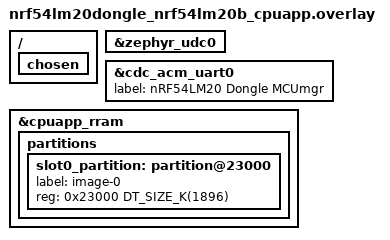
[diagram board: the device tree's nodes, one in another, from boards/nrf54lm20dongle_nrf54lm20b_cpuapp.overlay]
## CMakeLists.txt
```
#
# Copyright (c) 2026 Nordic Semiconductor ASA
#
# SPDX-License-Identifier: LicenseRef-Nordic-5-Clause
#

cmake_minimum_required(VERSION 3.20.0)
find_package(Zephyr REQUIRED HINTS $ENV{ZEPHYR_BASE})
project(usb_mcumgr)

target_sources(app PRIVATE ${ZEPHYR_BASE}/samples/subsys/mgmt/mcumgr/smp_svr/src/main.c)
target_sources_ifdef(CONFIG_SAMPLE_USB_MCUMGR_LED_THREAD app PRIVATE src/led_thread.c)
```

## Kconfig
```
#
# Copyright (c) 2026 Nordic Semiconductor ASA
#
# SPDX-License-Identifier: LicenseRef-Nordic-5-Clause
#

menu "USB MCUmgr firmware loader sample"

config SAMPLE_USB_MCUMGR_LED_THREAD
	bool "LED thread"
	default y if BOARD_NRF54LM20DONGLE
	depends on $(dt_alias_enabled,led0)
	select GPIO
	help
	  Start a low-priority thread that blinks the LED selected with the
	  devicetree alias "led0".

endmenu

source "Kconfig.zephyr"
```

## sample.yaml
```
sample:
  name: Minimal USB CDC-ACM SMP firmware loader sample
common:
  sysbuild: true
  build_only: true
tests:
  sample.fw_loader_usb_mcumgr:
    tags:
      - ci_samples_dfu
    platform_allow:
      - nrf54lm20dk/nrf54lm20a/cpuapp
      - nrf54lm20dongle/nrf54lm20b/cpuapp
    integration_platforms:
      - nrf54lm20dk/nrf54lm20a/cpuapp
      - nrf54lm20dongle/nrf54lm20b/cpuapp
```

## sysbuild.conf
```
# Enable MCUboot bootloader support
SB_CONFIG_BOOTLOADER_MCUBOOT=y
SB_CONFIG_PARTITION_MANAGER=n
SB_CONFIG_MCUBOOT_SYSBUILD_SIGN=n
```

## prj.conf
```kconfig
# Enable MCUmgr and dependencies.
CONFIG_NET_BUF=y
CONFIG_ZCBOR=y
CONFIG_CRC=y
CONFIG_MCUMGR=y
CONFIG_STREAM_FLASH=y
CONFIG_FLASH_MAP=y

# Some command handlers require a large stack.
CONFIG_SYSTEM_WORKQUEUE_STACK_SIZE=2304
CONFIG_MAIN_STACK_SIZE=2176

# Ensure an MCUboot-compatible binary is generated.
CONFIG_BOOTLOADER_MCUBOOT=y

# Enable flash operations.
CONFIG_FLASH=y

# Enable most core commands.
CONFIG_IMG_MANAGER=y
CONFIG_MCUMGR_GRP_IMG=y
CONFIG_MCUMGR_GRP_OS=y
CONFIG_MCUMGR_GRP_OS_BOOTLOADER_INFO=y
CONFIG_MCUMGR_GRP_OS_ECHO=n
CONFIG_MCUMGR_GRP_OS_INFO=n

# Enable the Shell mcumgr transport.
CONFIG_BASE64=y
CONFIG_CRC=y

CONFIG_MCUMGR_TRANSPORT_NETBUF_SIZE=1220
CONFIG_MCUMGR_GRP_OS_MCUMGR_PARAMS=y
CONFIG_MCUMGR_TRANSPORT_WORKQUEUE_STACK_SIZE=4608

# Enable the storage erase command.
CONFIG_MCUMGR_GRP_ZBASIC=y
CONFIG_MCUMGR_GRP_ZBASIC_STORAGE_ERASE=y

# Disable shell commands that are not needed
CONFIG_CLOCK_CONTROL_NRF_SHELL=n
CONFIG_DEVICE_SHELL=n
CONFIG_DEVMEM_SHELL=n
CONFIG_FLASH_SHELL=n

# Disable unneeded drivers, peripherals and features to optimize for size
CONFIG_SIZE_OPTIMIZATIONS=y

# Enable LTO
CONFIG_LTO=y
CONFIG_ISR_TABLES_LOCAL_DECLARATION=y

CONFIG_I2C=n
CONFIG_WATCHDOG=n
CONFIG_SPI_NOR=n
CONFIG_GPIO=n

CONFIG_FPU=n

CONFIG_BOOT_BANNER=n
CONFIG_NCS_BOOT_BANNER=n
CONFIG_BOOT_DELAY=0
CONFIG_PRINTK=n

CONFIG_ARM_MPU=n

CONFIG_TIMESLICING=n
CONFIG_COMMON_LIBC_MALLOC=y
CONFIG_LOG=n

CONFIG_UART_CONSOLE=n
CONFIG_ASSERT=n

# Enable USB subsystem
CONFIG_SERIAL=y
CONFIG_UART_LINE_CTRL=y
CONFIG_CONSOLE=y
CONFIG_USB_DEVICE_STACK_NEXT=y
CONFIG_CDC_ACM_SERIAL_INITIALIZE_AT_BOOT=y
# USB backend is serial device
CONFIG_UART_MCUMGR=y
CONFIG_MCUMGR_TRANSPORT_UART=y


CONFIG_PSA_USE_CRACEN_CIPHER_DRIVER=n
CONFIG_PSA_USE_CRACEN_AEAD_DRIVER=n
CONFIG_PSA_USE_CRACEN_MAC_DRIVER=n
CONFIG_PSA_USE_CRACEN_KEY_AGREEMENT_DRIVER=n
CONFIG_PSA_USE_CRACEN_ASYMMETRIC_ENCRYPTION_DRIVER=n
CONFIG_PSA_USE_CRACEN_KEY_MANAGEMENT_DRIVER=n
CONFIG_PSA_USE_CRACEN_KEY_DERIVATION_DRIVER=n
CONFIG_PSA_USE_CRACEN_PAKE_DRIVER=n
CONFIG_PSA_USE_CRACEN_ASYMMETRIC_SIGNATURE_DRIVER=n
CONFIG_PSA_USE_CRACEN_HASH_DRIVER=n
```

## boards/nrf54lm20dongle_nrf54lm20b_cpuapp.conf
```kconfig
#
# Copyright (c) 2026 Nordic Semiconductor ASA
#
# SPDX-License-Identifier: LicenseRef-Nordic-5-Clause
#
CONFIG_CDC_ACM_SERIAL_VID=0x1915
CONFIG_CDC_ACM_SERIAL_PID=0x541A
CONFIG_CDC_ACM_SERIAL_MANUFACTURER_STRING="Nordic Semiconductor ASA"
CONFIG_CDC_ACM_SERIAL_PRODUCT_STRING="nRF54LM20 Dongle Bootloader"
CONFIG_MCUMGR_GRP_ZBASIC_STORAGE_ERASE=n
```

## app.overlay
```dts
/*
 * Copyright (c) 2026 Nordic Semiconductor ASA
 *
 * SPDX-License-Identifier: LicenseRef-Nordic-5-Clause
 */

/ {
	chosen {
		zephyr,uart-mcumgr = &cdc_acm_uart0;
	};
};

&zephyr_udc0 {
	cdc_acm_uart0: cdc_acm_uart0 {
		compatible = "zephyr,cdc-acm-uart";
	};
};
```

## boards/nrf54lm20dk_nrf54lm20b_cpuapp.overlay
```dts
/*
 * Copyright (c) 2026 Nordic Semiconductor ASA
 *
 * SPDX-License-Identifier: LicenseRef-Nordic-5-Clause
 */

/delete-node/ &boot_partition;
/delete-node/ &slot0_partition;
/delete-node/ &slot1_partition;
/delete-node/ &storage_partition;

&cpuapp_rram {
	reg = <0x0 DT_SIZE_K(1940)>;

	partitions {
		boot_partition: partition@0 {
			compatible = "zephyr,mapped-partition";
			label = "mcuboot";
			reg = <0x0 DT_SIZE_K(24)>;
		};

		slot0_partition: partition@6000 {
			compatible = "zephyr,mapped-partition";
			label = "image-0";
			reg = <0x6000 DT_SIZE_K(1776)>;
		};

		slot1_partition: partition@1c2000 {
			compatible = "zephyr,mapped-partition";
			label = "image-1";
			reg = <0x1c2000 DT_SIZE_K(124)>;
		};

		storage_partition: partition@1e1000 {
			compatible = "zephyr,mapped-partition";
			label = "storage";
			reg = <0x1e1000 DT_SIZE_K(16)>;
		};
	};
};

#include "../app.overlay"
```

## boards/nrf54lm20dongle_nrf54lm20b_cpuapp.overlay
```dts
/*
 * Copyright (c) 2026 Nordic Semiconductor ASA
 *
 * SPDX-License-Identifier: LicenseRef-Nordic-5-Clause
 */

/ {
	chosen {
		/delete-property/ zephyr,console;
		/delete-property/ zephyr,shell-uart;
		/delete-property/ zephyr,bt-mon-uart;
		/delete-property/ zephyr,bt-c2h-uart;
	};
};

&zephyr_udc0 {
	/delete-node/ board_cdc_acm_uart;
	/delete-node/ mcumgr_cdc_acm_uart;
};

#include "../app.overlay"

&cdc_acm_uart0 {
	label = "nRF54LM20 Dongle MCUmgr";
};

/* This is nRF54lm20dongle_nrf54lm20b_cpuapp-specific partitioning for MCUboot and firmware loader.
 * slot0_partition defines RRAM region which can be updated by the firmware loader and booted by
 * MCUboot.
 * Beginning of the slot0_partition must match the beginning of the slot0_partition of the user
 * application, but the application can use a smaller partition and leave some space for
 * other purposes like a storage partition.
 */

/delete-node/ &storage_partition;

&cpuapp_rram {
	partitions {
		slot0_partition: partition@23000 {
			label = "image-0";
			reg = <0x23000 DT_SIZE_K(1896)>;
		};
	};
};
```

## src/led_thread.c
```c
/*
 * Copyright (c) 2026 Nordic Semiconductor ASA
 *
 * SPDX-License-Identifier: LicenseRef-Nordic-5-Clause
 */

#include <zephyr/devicetree.h>
#include <zephyr/drivers/gpio.h>
#include <zephyr/kernel.h>

#define LED0_NODE DT_ALIAS(led0)

#define LED_THREAD_STACK_SIZE 512
#define LED_THREAD_BLINK_MS   500
#define LED_THREAD_PRIORITY   K_LOWEST_APPLICATION_THREAD_PRIO

static const struct gpio_dt_spec led = GPIO_DT_SPEC_GET(LED0_NODE, gpios);

static void led_thread_fn(void *p1, void *p2, void *p3)
{
	ARG_UNUSED(p1);
	ARG_UNUSED(p2);
	ARG_UNUSED(p3);

	if (!gpio_is_ready_dt(&led)) {
		return;
	}

	if (gpio_pin_configure_dt(&led, GPIO_OUTPUT_INACTIVE) != 0) {
		return;
	}

	while (true) {
		gpio_pin_toggle_dt(&led);
		k_sleep(K_MSEC(LED_THREAD_BLINK_MS));
	}
}

K_THREAD_DEFINE(usb_mcumgr_led_thread, LED_THREAD_STACK_SIZE,
		led_thread_fn, NULL, NULL, NULL,
		LED_THREAD_PRIORITY, 0, 0);
```
